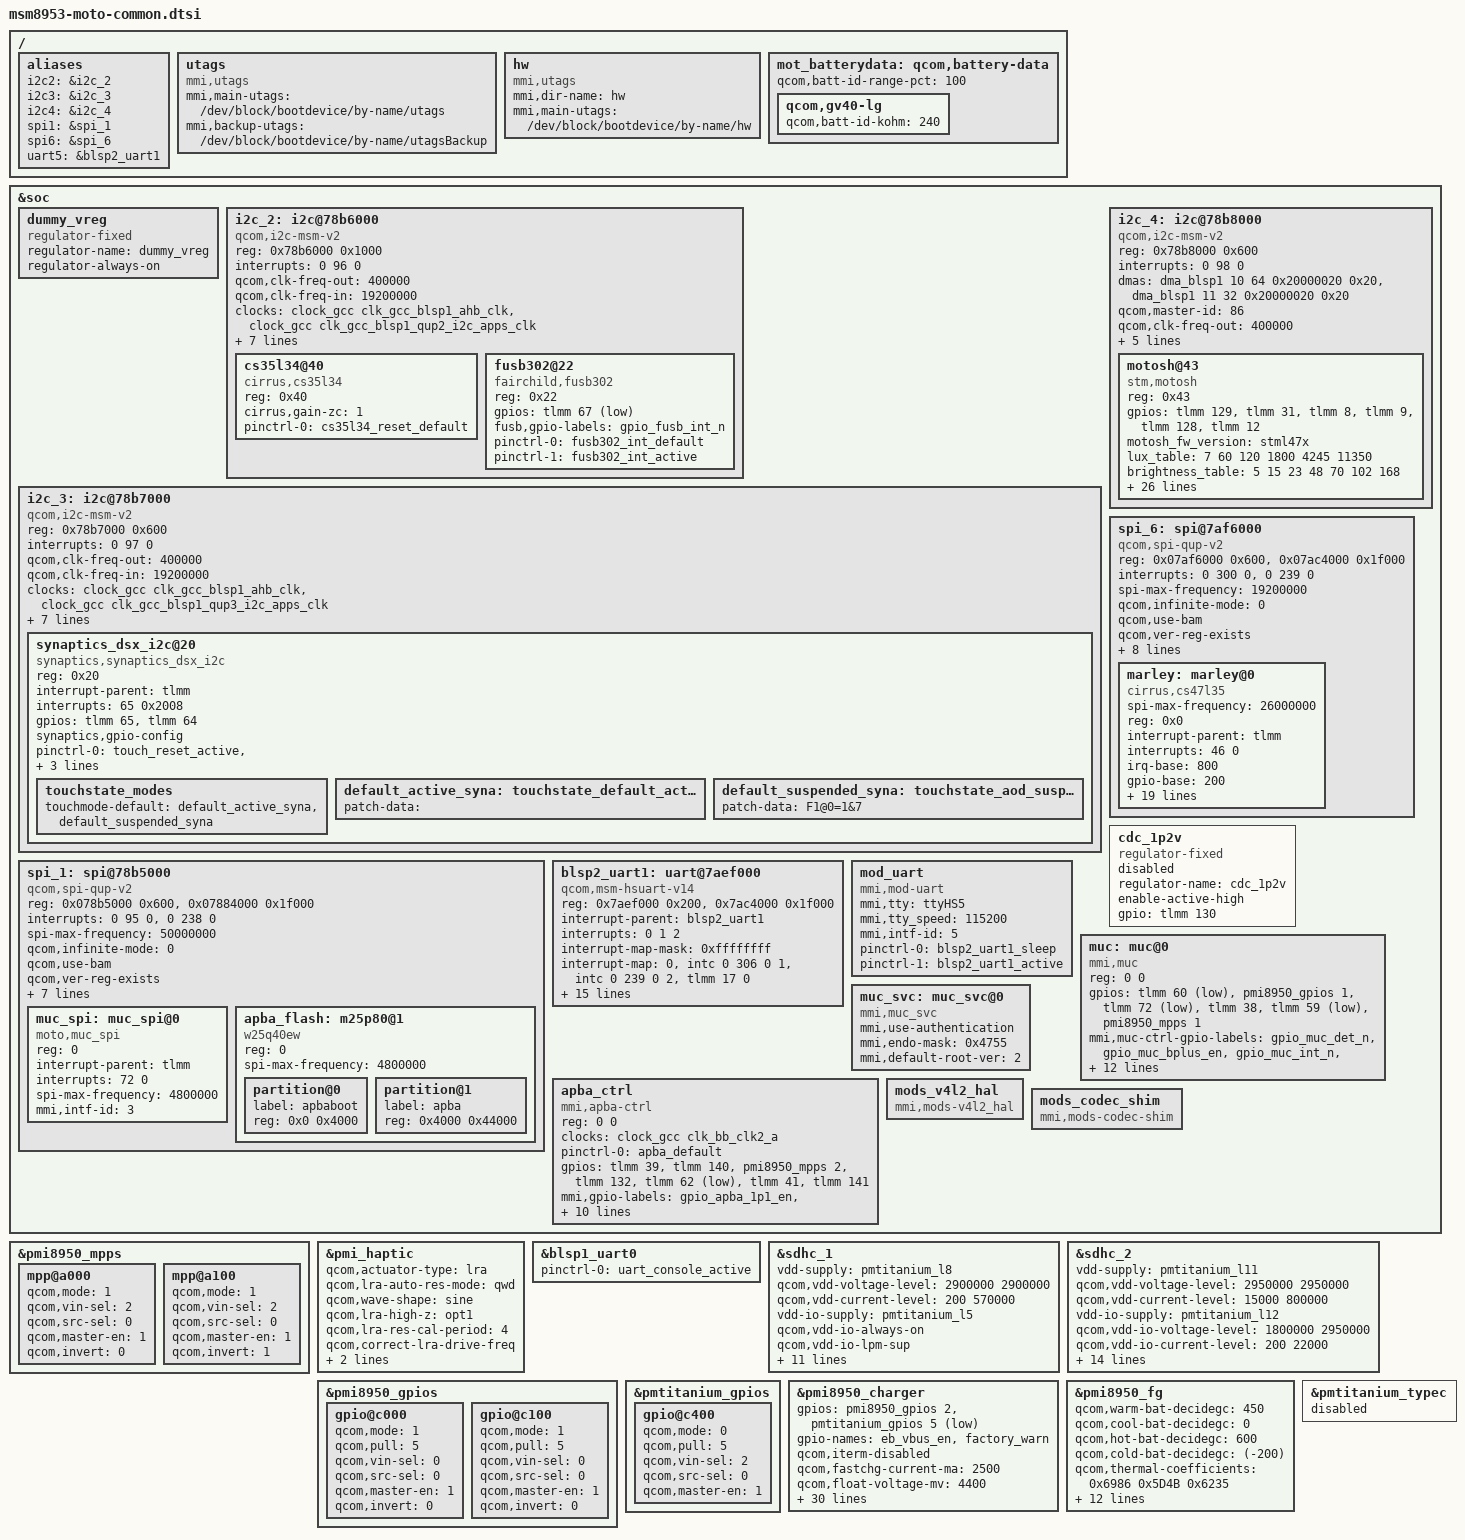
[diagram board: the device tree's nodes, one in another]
/* Copyright (c) 2016, Motorola Mobility Inc. All rights reserved.
 *
 * This program is free software; you can redistribute it and/or modify
 * it under the terms of the GNU General Public License version 2 and
 * only version 2 as published by the Free Software Foundation.
 *
 * This program is distributed in the hope that it will be useful,
 * but WITHOUT ANY WARRANTY; without even the implied warranty of
 * MERCHANTABILITY or FITNESS FOR A PARTICULAR PURPOSE.  See the
 * GNU General Public License for more details.
 */

#include "msmtitanium.dtsi"
#include "msmtitanium-pinctrl.dtsi"
#include "msm8953-moto-pinctrl.dtsi"

/ {
	aliases {
		i2c2 = &i2c_2;
		i2c3 = &i2c_3;
		i2c4 = &i2c_4;
		spi1 = &spi_1;
		spi6 = &spi_6;
		uart5 = &blsp2_uart1;
		/delete-property/ spi3;
		/delete-property/ i2c5;
	};

	utags {
		compatible = "mmi,utags";
		mmi,main-utags = "/dev/block/bootdevice/by-name/utags";
		mmi,backup-utags = "/dev/block/bootdevice/by-name/utagsBackup";
	};

	hw {
		compatible = "mmi,utags";
		mmi,dir-name = "hw";
		mmi,main-utags = "/dev/block/bootdevice/by-name/hw";
	};

};

&soc{
	/delete-node/ uart@78b0000;
	/delete-node/ i2c@7af5000;
	/delete-node/ spi@78b7000;
	/delete-node/ adv_vreg;

	dummy_vreg: dummy_vreg {
		compatible = "regulator-fixed";
		status = "ok";
		regulator-name = "dummy_vreg";
		regulator-always-on;
	};

	i2c_2: i2c@78b6000 { /* BLSP1 QUP2 */
		compatible = "qcom,i2c-msm-v2";
		#address-cells = <1>;
		#size-cells = <0>;
		reg-names = "qup_phys_addr";
		reg = <0x78b6000 0x1000>;
		interrupt-names = "qup_irq";
		interrupts = <0 96 0>;
		qcom,clk-freq-out = <400000>;
		qcom,clk-freq-in  = <19200000>;
		clock-names = "iface_clk", "core_clk";
		clocks = <&clock_gcc clk_gcc_blsp1_ahb_clk>,
			<&clock_gcc clk_gcc_blsp1_qup2_i2c_apps_clk>;

		pinctrl-names = "i2c_active", "i2c_sleep";
		pinctrl-0 = <&i2c_2_active>;
		pinctrl-1 = <&i2c_2_sleep>;
		qcom,noise-rjct-scl = <0>;
		qcom,noise-rjct-sda = <0>;
		qcom,master-id = <86>;
		dmas = <&dma_blsp1 6 64 0x20000020 0x20>,
			<&dma_blsp1 7 32 0x20000020 0x20>;
		dma-names = "tx", "rx";
		cs35l34@40 {
			compatible = "cirrus,cs35l34";
			reg = <0x40>;

			cirrus,gain-zc = <1>;
			pinctrl-names = "default";
			pinctrl-0 = <&cs35l34_reset_default>;
		};

		fusb302@22 {
			compatible = "fairchild,fusb302";
			reg = <0x22>;
			gpios = <&tlmm 67 1>; /* FUSB302_INT_N, in */
			fusb,gpio-labels = "gpio_fusb_int_n";
			pinctrl-names = "default", "active";
			pinctrl-0 = <&fusb302_int_default>;
			pinctrl-1 = <&fusb302_int_active>;
		};

		/delete-node/ adv7533@39;
	};

	i2c_3: i2c@78b7000 { /* BLSP1 QUP3 */
		status = "okay";
		compatible = "qcom,i2c-msm-v2";
		#address-cells = <1>;
		#size-cells = <0>;
		reg-names = "qup_phys_addr";
		reg = <0x78b7000 0x600>;
		interrupt-names = "qup_irq";
		interrupts = <0 97 0>;
		qcom,clk-freq-out = <400000>;
		qcom,clk-freq-in  = <19200000>;
		clock-names = "iface_clk", "core_clk";
		clocks = <&clock_gcc clk_gcc_blsp1_ahb_clk>,
			<&clock_gcc clk_gcc_blsp1_qup3_i2c_apps_clk>;

		pinctrl-names = "i2c_active", "i2c_sleep";
		pinctrl-0 = <&i2c_3_active>;
		pinctrl-1 = <&i2c_3_sleep>;
		qcom,noise-rjct-scl = <0>;
		qcom,noise-rjct-sda = <0>;
		qcom,master-id = <86>;
		dmas = <&dma_blsp1 8 64 0x20000020 0x20>,
			<&dma_blsp1 9 32 0x20000020 0x20>;
		dma-names = "tx", "rx";
		synaptics_dsx_i2c@20 {
			compatible = "synaptics,synaptics_dsx_i2c";
			reg = <0x20>;
			interrupt-parent = <&tlmm>;
			interrupts = <65 0x2008>;
			gpios = <&tlmm 65 0x2008>, /* IRQ */
				<&tlmm 64 0>; /* RESET */
			synaptics,gpio-config;
			pinctrl-names = "default", "active";
			pinctrl-0 = <&touch_reset_active &touch_int_default>;
			pinctrl-1 = <&touch_reset_active &touch_int_active>;
			touchstate_modes {
				touchmode-default = <&default_active_syna &default_suspended_syna>;
			};
			default_active_syna: touchstate_default_active {
				patch-data = "";
			};
			default_suspended_syna: touchstate_aod_suspended {
				patch-data = "F1@0=1&7";
			};
		};

	};

	/* SensorHub Bus */
	i2c_4: i2c@78b8000 {
		/* BLSP1 QUP4, however QC refers to this address as:
		   HWID BLSP4 - BLSP1 QUP3
		*/
		status = "okay";
		compatible = "qcom,i2c-msm-v2";
		#address-cells = <1>;
		#size-cells = <0>;
		reg-names = "qup_phys_addr";
		reg = <0x78b8000 0x600>;
		interrupt-names = "qup_irq";
		interrupts = <0 98 0>;
		dmas = <&dma_blsp1 10 64 0x20000020 0x20>,
			<&dma_blsp1 11 32 0x20000020 0x20>;
		dma-names = "tx", "rx";
		qcom,master-id = <86>;
		qcom,clk-freq-out = <400000>;
		qcom,clk-freq-in  = <19200000>;
		clock-names = "iface_clk", "core_clk";
		clocks = <&clock_gcc clk_gcc_blsp1_ahb_clk>,
			 <&clock_gcc clk_gcc_blsp1_qup4_i2c_apps_clk>;
		pinctrl-names = "i2c_active", "i2c_sleep";
		pinctrl-0 = <&i2c_4_active>;
		pinctrl-1 = <&i2c_4_sleep>;

		motosh@43 {
			compatible = "stm,motosh";
			reg = <0x43>;
			gpios = <&tlmm 129 0>,  /* IRQ     CCP_AP_INT2  */
				<&tlmm  31 0>,  /* RESET   CCP_FAULT_N  */
				<&tlmm   8 0>,  /* BSLEN   CCP_FLASH_EN */
				<&tlmm   9 0>,  /* WakeIRQ CCP_AP_INT   */
				<&tlmm 128 0>,  /* SH Wake AP_CCP_WAKE  */
				<&tlmm  12 0>;  /* SH Wake Resp CCP_AP_WAKE */
			motosh_fw_version = "stml47x";
			lux_table = <7 60 120 1800 4245 11350>;
			brightness_table = <5 15 23 48 70 102 168>;
			qd_pm_qos_latency = <350>;
			qd_pm_qos_timeout = <500000>;
			bslen_pin_active_value = <1>;
			ct406_detect_threshold = <0x006E>;
			ct406_undetect_threshold = <0x0050>;
			ct406_recalibrate_threshold = <0x0064>;
			ct406_pulse_count = <0x02>;
			ct406_prox_gain = <0x02>;
			ct406_als_lux1_c0_mult = <0x46E>;
			ct406_als_lux1_c1_mult = <0x85A>;
			ct406_als_lux1_div = <0x80>;
			ct406_als_lux2_c0_mult = <0x11F>;
			ct406_als_lux2_c1_mult = <0x1DE>;
			ct406_als_lux2_div = <0x80>;
			sensor1-supply = <&pmtitanium_l6>;
			sensor2-supply = <&pmtitanium_l22>;
			accel_orient = <1>;     /* Accel Orientation value */
			gyro_orient = <1>;      /* Gyro Orientation value */
			mag_orient =  <2>;      /* Mag Orientation value */
			mag_config = <0>;       /* Magnetometer config value */
			panel_type = <1>;       /* Panel Type value */
			IR_config = <1>;        /* IR Config value */
			cover_detect_polarity = <2>; /*MOTOSH_NORTH_DETECT*/
			pinctrl-names = "default";
			pinctrl-0 = <&pmx_motosh_out &pmx_motosh_in>;
			antcap_cfg = [54 21 03 00 00 0a 52 00 00 0b e7 00 00 09 9f 00 00 12 74 13 88 00 00 00 00 80 00 14 1e 00 a4 13 ec 00 00 00 00 00 de ad be ef 00 00 00 00 00 00 00 00 00 00 00 00 00 00 00 00 00 00 00 00 00 00 ];
		};
	};

	spi_6: spi@7af6000 { /* BLSP2 QUP2 */
		status = "ok";
		compatible = "qcom,spi-qup-v2";
		#address-cells = <1>;
		#size-cells = <0>;
		reg-names = "spi_physical", "spi_bam_physical";
		reg = <0x07af6000 0x600>,
		<0x07ac4000 0x1f000>;
		interrupt-names = "spi_irq", "spi_bam_irq";
		interrupts = <0 300 0>, <0 239 0>;
		spi-max-frequency = <19200000>;

		qcom,infinite-mode = <0>;
		qcom,use-bam;
		qcom,ver-reg-exists;
		qcom,bam-consumer-pipe-index = <6>;
		qcom,bam-producer-pipe-index = <7>;
		qcom,master-id = <84>;
		qcom,use-pinctrl;
		pinctrl-names = "spi_default", "spi_sleep";
		pinctrl-0 = <&spi_6_active &spi6_cs0_active>;
		pinctrl-1 = <&spi_6_sleep &spi6_cs0_sleep>;

		clock-names = "iface_clk", "core_clk";

		clocks = <&clock_gcc clk_gcc_blsp2_ahb_clk>,
			<&clock_gcc clk_gcc_blsp2_qup2_spi_apps_clk>;

		marley: marley@0 {
			compatible = "cirrus,cs47l35";
			spi-max-frequency = <26000000>;
			reg = <0x0>;
			interrupt-parent = <&tlmm>;
			interrupts = <46 0>;
			irq-base = <800>;
			gpio-base = <200>;
			wlf,reset = <&tlmm 68 0>;
			wlf,irq = <&tlmm 46 0>;
			wlf,out-mono = <0 1 0 0 0 0>;
			wlf,micbias1 = <1800 1 1 0 0>;
			wlf,micbias2 = <1800 1 1 0 0>;
			wlf,micbias3 = <1800 1 1 0 0>;
			vreg-arizona1p2-supply = <&dummy_vreg>;
			pinctrl-names = "default";
			pinctrl-0 = <&marley_irq_default &marley_reset_default>;

			AVDD-supply = <&pmtitanium_l6>;
			DBVDD1-supply = <&pmtitanium_l6>;
			DBVDD2-supply = <&pmtitanium_l6>;
			CPVDD-supply = <&pmtitanium_l6>;
			CPVDD1-supply = <&pmtitanium_l6>;
			CPVDD2-supply = <&pmtitanium_l6>;
			DCVDD-supply = <&pmtitanium_l6>;
			SPKVDDL-supply = <&dummy_vreg>;
			SPKVDDR-supply = <&dummy_vreg>;

			gpio-controller;
			#gpio-cells = <2>;
		};
	};

	/* currus 1.2V supply TPS6267001 */
	cdc_1p2v: cdc_1p2v {
		status = "disabled";
		compatible = "regulator-fixed";
		regulator-name = "cdc_1p2v";
		enable-active-high;
		gpio = <&tlmm 130 0>;
	};

	spi_1: spi@78b5000 { /* BLSP1 QUP1 */
		status = "ok";
		compatible = "qcom,spi-qup-v2";
		#address-cells = <1>;
		#size-cells = <0>;
		reg-names = "spi_physical", "spi_bam_physical";
		reg = <0x078b5000 0x600>,
		<0x07884000 0x1f000>;
		interrupt-names = "spi_irq", "spi_bam_irq";
		interrupts = <0 95 0>, <0 238 0>;
		spi-max-frequency = <48000000>;

		qcom,infinite-mode = <0>;
		qcom,use-bam;
		qcom,ver-reg-exists;
		qcom,bam-consumer-pipe-index = <4>;
		qcom,bam-producer-pipe-index = <5>;
		qcom,master-id = <86>;
		qcom,use-pinctrl;
		pinctrl-names = "spi_default", "spi_sleep";
		pinctrl-0 = <&spi_1_active &spi1_cs0_sleep &spi1_cs1_sleep>;
		pinctrl-1 = <&spi_1_sleep &spi1_cs0_sleep &spi1_cs1_sleep>;

		clock-names = "iface_clk", "core_clk";

		clocks = <&clock_gcc clk_gcc_blsp1_ahb_clk>,
			<&clock_gcc clk_gcc_blsp1_qup1_spi_apps_clk>;
	};

	blsp2_uart1: uart@7aef000 { /* BLSP2 UART1 */
		compatible = "qcom,msm-hsuart-v14";
		reg = <0x7aef000 0x200>,
			<0x7ac4000 0x1f000>;
		reg-names = "core_mem", "bam_mem";

		interrupt-names = "core_irq", "bam_irq", "wakeup_irq";
		#address-cells = <0>;
		interrupt-parent = <&blsp2_uart1>;
		interrupts = <0 1 2>;
		#interrupt-cells = <1>;
		interrupt-map-mask = <0xffffffff>;
		interrupt-map = <0 &intc 0 306 0
				1 &intc 0 239 0
				2 &tlmm 17 0>;

		qcom,tx-gpio = <&tlmm 16 0>;
		qcom,rx-gpio = <&tlmm 17 1>;
		qcom,cts-gpio = <&tlmm 18 0>;
		qcom,rts-gpio = <&tlmm 19 1>;
		qcom,master-id = <84>;
		clock-names = "core_clk", "iface_clk";
		clocks = <&clock_gcc clk_gcc_blsp2_uart1_apps_clk>,
			<&clock_gcc clk_gcc_blsp2_ahb_clk>;
		qcom,bam-tx-ep-pipe-index = <0>;
		qcom,bam-rx-ep-pipe-index = <1>;
		qcom,msm-bus,name = "blsp2_uart1";
		qcom,msm-bus,num-cases = <2>;
		qcom,msm-bus,num-paths = <1>;
		qcom,msm-bus,vectors-KBps =
				<84 512 0 0>,
				<84 512 500 800>;
		status = "ok";
	};

	mod_uart {
		compatible = "mmi,mod-uart";
		mmi,tty = "ttyHS5";
		mmi,tty_speed = <115200>;
		mmi,intf-id = /bits/ 8 <5>;

		pinctrl-names = "default", "active";
		pinctrl-0 = <&blsp2_uart1_sleep>;
		pinctrl-1 = <&blsp2_uart1_active>;
	};

	muc: muc@0 {
		compatible = "mmi,muc";
		reg = <0 0>;

		gpios = <&tlmm 60 1>,          /* gpio_muc_det_n, input */
			<&pmi8950_gpios 1 0>,  /* gpio_muc_bplus_en, output-low */
			<&tlmm 72 1>,          /* gpio_muc_int_n, input */
			<&tlmm 38 2>,          /* gpio_muc_wake_n, output-high */
			<&tlmm 59 1>,          /* gpio_muc_rdy_n, input */
			<&pmi8950_mpps 1 0>;   /* gpio_muc_ff, output-low */
		mmi,muc-ctrl-gpio-labels = "gpio_muc_det_n",
					"gpio_muc_bplus_en",
					"gpio_muc_int_n",
					"gpio_muc_wake_n",
					"gpio_muc_rdy_n",
					"gpio_muc_ff";

		mmi,muc-ctrl-det-hysteresis = <500>;
		mmi,muc-ctrl-en-seq = <1 0 200>, <1 1 1000>;
		mmi,muc-ctrl-dis-seq = <1 0 200>;

		/* v1 FF first, BPLUS second on enable */
		mmi,muc-ctrl-ff-seq-v1 = <5 1 20>, <1 0 100>,
					<1 1 100>, <5 0 20>;

		/* v2 BPLUS first, FF second on enable */
		mmi,muc-ctrl-ff-seq-v2 = <5 0 20>, <1 0 20>,
					<1 1 100>, <5 1 20>,
					<5 0 20>;

		pinctrl-names = "disconnected", "spi_active";
		pinctrl-0 = <&muc_attach &spi_1_sleep &muc_spi_ctrl>;
		pinctrl-1 = <&muc_attach &spi_1_active &muc_spi_ctrl>;
	};

	muc_svc: muc_svc@0 {
		compatible = "mmi,muc_svc";

		mmi,use-authentication;
		mmi,endo-mask = <0x4755>;
		mmi,default-root-ver = /bits/ 8 <2>;
	};

	apba_ctrl {
		compatible = "mmi,apba-ctrl";
		reg = <0 0>;
		clock-names = "apba_mclk";
		clocks = <&clock_gcc clk_bb_clk2_a>;
		pinctrl-names = "default";
		pinctrl-0 = <&apba_default>;
		gpios = <&tlmm 39 2>,      /* APBA_1P1_EN, output-high */
			<&tlmm 140 0>,     /* APBA_BOOTRET, output-low */
			<&pmi8950_mpps 2 2>, /* MOD_MPHY_I2S_SEL, output-high */
			<&tlmm 132 0>,     /* APBA_RESET_N, output-low */
			<&tlmm 62 1>,      /* APBA_INT_N, in */
			<&tlmm 41 2>,      /* APBA_SFLASH_EN, output-high */
			<&tlmm 141 2>;     /* APBA_WAKE, output-high */
		mmi,gpio-labels = "gpio_apba_1p1_en",
				  "gpio_apba_bootret",
				  "gpio_mphy_i2s_sel",
				  "gpio_apba_rst_n",
				  "gpio_apba_int_n",
				  "gpio_apba_sflash_en",
				  "gpio_apba_wake";
		mmi,int-index = <4>;
		mmi,enable-seq = <5 1 0>, <0 1 0>, <1 0 0>, <2 0 0>, <3 0 50>,
				 <3 1 50>;
		mmi,disable-seq = <1 0 0>, <2 1 0>, <3 0 50>, <5 0 0>, <0 0 0>;
		mmi,wake-assert-seq = <5 0 0>;
		mmi,wake-deassert-seq = <5 1 0>;
	};

	mods_v4l2_hal {
		compatible = "mmi,mods-v4l2_hal";
	};

	mods_codec_shim {
		compatible = "mmi,mods-codec-shim";
	};
};

&pmi8950_mpps {
	mpp@a000 { /* MPP1 MOD_MPHY_I2S_EN */
		qcom,mode = <1>;	/* Digital output */
		qcom,vin-sel = <2>;	/* 1.8 */
		qcom,src-sel = <0>;	/* GPIO */
		qcom,master-en = <1>;	/* Enable GPIO */
		qcom,invert = <0>;	/* Output low (disabled) */
		status = "okay";
	};

	mpp@a100 { /* MPP2 MOD_MPHY_I2S_SEL */
		qcom,mode = <1>;	/* Digital output */
		qcom,vin-sel = <2>;	/* 1.8 */
		qcom,src-sel = <0>;	/* GPIO */
		qcom,master-en = <1>;	/* Enable GPIO */
		qcom,invert = <1>;	/* Output high */
		status = "okay";
	};
};

&spi_1 {
	/delete-property/ pinctrl-0;
	/delete-property/ pinctrl-1;
	/delete-property/ pinctrl-names;
	/delete-property/ qcom,use-pinctrl;

	spi-max-frequency = <50000000>;

	qcom,rt-priority;
	qcom,active-only;

	muc_spi: muc_spi@0 {
		compatible = "moto,muc_spi";
		reg = <0>;
		interrupt-parent = <&tlmm>;
		interrupts = <72 0>;
		spi-max-frequency = <4800000>;

		mmi,intf-id = /bits/ 8 <3>;
	};

	apba_flash: m25p80@1 {
		compatible = "w25q40ew";
		reg = <0>;
		spi-max-frequency = <4800000>;

		#address-cells = <1>;
		#size-cells = <1>;
		partition@0 {
			label = "apbaboot";
			reg = <0x0 0x4000>;
		};
		partition@1 {
			label = "apba";
			reg = <0x4000 0x44000>;
		};
	};
};

&pmi_haptic{
	qcom,actuator-type = "lra";
	qcom,lra-auto-res-mode="qwd";
	qcom,wave-shape = "sine";
	qcom,lra-high-z="opt1";
	qcom,lra-res-cal-period = <4>;
	qcom,correct-lra-drive-freq;
	qcom,wave-play-rate-us = <4165>;
	qcom,vmax-mv = <2050>;
};

&blsp1_uart0 {
	status = "ok";
	pinctrl-names = "default";
	pinctrl-0 = <&uart_console_active>;
};

&sdhc_1 {
	/* device core power supply */
	vdd-supply = <&pmtitanium_l8>;
	qcom,vdd-voltage-level = <2900000 2900000>;
	qcom,vdd-current-level = <200 570000>;

	/* device communication power supply */
	vdd-io-supply = <&pmtitanium_l5>;
	qcom,vdd-io-always-on;
	qcom,vdd-io-lpm-sup;
	qcom,vdd-io-voltage-level = <1800000 1800000>;
	qcom,vdd-io-current-level = <200 325000>;

	pinctrl-names = "active", "sleep";
	pinctrl-0 = <&sdc1_clk_on &sdc1_cmd_on &sdc1_data_on  &sdc1_rclk_on>;
	pinctrl-1 = <&sdc1_clk_off &sdc1_cmd_off &sdc1_data_off &sdc1_rclk_off>;

	qcom,clk-rates = <400000 20000000 25000000 50000000 100000000 192000000
								384000000>;
	qcom,nonremovable;
	qcom,bus-speed-mode = "HS400_1p8v", "HS200_1p8v", "DDR_1p8v";

	status = "ok";
};

&sdhc_2 {
	/* device core power supply */
	vdd-supply = <&pmtitanium_l11>;
	qcom,vdd-voltage-level = <2950000 2950000>;
	qcom,vdd-current-level = <15000 800000>;

	/* device communication power supply */
	vdd-io-supply = <&pmtitanium_l12>;
	qcom,vdd-io-voltage-level = <1800000 2950000>;
	qcom,vdd-io-current-level = <200 22000>;

	pinctrl-names = "active", "sleep";
	pinctrl-0 = <&sdc2_clk_on &sdc2_cmd_on &sdc2_data_on &sdc2_cd_off>;
	pinctrl-1 = <&sdc2_clk_off &sdc2_cmd_off &sdc2_data_off &sdc2_cd_off>;

	#address-cells = <0>;
	interrupt-parent = <&sdhc_2>;
	interrupts = <0 1 2>;
	#interrupt-cells = <1>;
	interrupt-map-mask = <0xffffffff>;
	interrupt-map = <0 &intc 0 125 0
		1 &intc 0 221 0
		2 &tlmm 133 0>;
	interrupt-names = "hc_irq", "pwr_irq", "status_irq";
	cd-gpios = <&tlmm 133 0x0>;

	qcom,clk-rates = <400000 20000000 25000000 50000000 100000000
								192000000>;
	qcom,bus-speed-mode = "SDR12", "SDR25", "SDR50", "DDR50", "SDR104";

	status = "ok";
};


&pmi8950_gpios {
	gpio@c000 { /* GPIO 1 - MOD_BPLUS_EN */
		qcom,mode = <1>;	/* Digital output */
		qcom,pull = <5>;	/* No Pull */
		qcom,vin-sel = <0>;	/* 1.8 */
		qcom,src-sel = <0>;	/* GPIO */
		qcom,master-en = <1>;	/* Enable GPIO */
		qcom,invert = <0>;	/* Output Low */
		status = "okay";
	};

	gpio@c100 {
		qcom,mode = <1>;	/* Digital output */
		qcom,pull = <5>;	/* No Pull */
		qcom,vin-sel = <0>;	/* 1.8 */
		qcom,src-sel = <0>;	/* GPIO */
		qcom,master-en = <1>;	/* Enable GPIO */
		qcom,invert = <0>;	/* Output Low */
		status = "okay";
	};
};

&pmi8950_mpps {
	mpp@a000 { /* MPP 1 - MOD_F_FLASH */
		qcom,mode = <1>;	/* Digital output */
		qcom,vin-sel = <2>;	/* 1.8 */
		qcom,src-sel = <0>;	/* GPIO */
		qcom,master-en = <1>;	/* Enable GPIO */
		qcom,invert = <0>;	/* Output low */
		status = "okay";
	};
};

&pmtitanium_gpios {
	gpio@c400 {
		qcom,mode = <0>;		/* Digital Input */
		qcom,pull = <5>;		/* No pull  */
		qcom,vin-sel = <2>;		/* VIN0 */
		qcom,src-sel = <0>;		/* GPIO */
		qcom,master-en = <1>;		/* Enable GPIO */
		status = "okay";
	};
};

&pmi8950_charger {
	status = "okay";
	gpios = <&pmi8950_gpios 2 0x0>, /* GPIOF_OUT_INIT_LOW */
		<&pmtitanium_gpios 5 0x1>; /* GPIOF_IN */
	gpio-names = "eb_vbus_en",
		     "factory_warn";
	/delete-property/ qcom,iterm-ma;
	qcom,iterm-disabled;
	/delete-property/ qcom,autoadjust-vfloat;
	qcom,fastchg-current-ma = <2500>;
	qcom,float-voltage-mv = <4400>;
	qcom,resume-delta-mv = <200>;
	qcom,chg-inhibit-fg;
	qcom,rparasitic-uohm = <100000>;
	qcom,bms-psy-name = "bms";
	qcom,eb-batt-psy-name = "gb_battery";
	qcom,eb-pwr-psy-name = "gb_ptp";
	qcom,charge-unknown-battery;
	qcom,chg-thermal-mitigation = <2500>, <2000>, <1600>, <1200>, <1000>, <700>,
				      <500>, <300>;
	qcom,dc-thermal-mitigation = <950>, <700>, <600>, <500>, <400>, <300>;
	qcom,parallel-charge-current-map = <2500 2500 0>,
					   <2000 2000 0>,
					   <1600 1600 0>,
					   <1200 1200 0>,
					   <1000 1000 0>,
					   <700 700 0>,
					   <500 500 0>,
					   <300 300 0>;
	qcom,step-chg-steps = <4200 2500 1800>,
				<4400 1800 1500>;
	qcom,stepchg-iterm-ma = <200>;
	qcom,hot-temp-c = <60>;
	qcom,cold-temp-c = <(-20)>;
	qcom,warm-temp-c = <45>;
	qcom,cool-temp-c = <0>;
	qcom,ext-temp-volt-mv = <4200>;
	qcom,hotspot-thrs-c = <50>;
	qcom,charging-timeout-mins = <0>;
	qcom,precharging-timeout-mins = <0>;
	qcom,bmd-algo-disabled;
	qcom,bmd-pin-src = "bpd_none";
	qcom,usbid-disabled;
	qcom,force-aicl-rerun;
	mmi,fake-factory-type;
};

/{
	mot_batterydata: qcom,battery-data {
		qcom,batt-id-range-pct = <100>;
		#include "batterydata-gv40-lg.dtsi"
	};
};

&mot_batterydata{
	qcom,gv40-lg {
		qcom,batt-id-kohm = <240>;
	};
};

&pmi8950_fg {
	status = "okay";
	qcom,warm-bat-decidegc = <450>;
	qcom,cool-bat-decidegc = <0>;
	qcom,hot-bat-decidegc = <600>;
	qcom,cold-bat-decidegc = <(-200)>;
	qcom,thermal-coefficients =  /bits/ 16 <0x6986 0x5D4B 0x6235>;
	qcom,resume-soc = <99>;
	qcom,bcl-lm-threshold-ma = <126>;
	qcom,bcl-mh-threshold-ma = <400>;
	qcom,fg-iterm-ma = <150>;
	qcom,irq-volt-empty-mv = <2750>;
	qcom,fg-cutoff-voltage-mv = <3000>;
	qcom,fg-vbat-estimate-diff-mv = <1000>;
	qcom,fg-delta-soc = <1>;
	qcom,fg-max-soc = <100>;
	qcom,fg-min-soc = <0>;
	qcom,fg-cc-cv-threshold-mv = <4390>;
	qcom,battery-data = <&mot_batterydata>;
};

&pmtitanium_typec {
	status = "disabled";
};
